# HDSC_HC32M423 register map
Vendor: HDSC Co.,Ltd.; Series: ARMCM4; File version: 1.0
CPU: CM4 r0p1, little endian, MPU, FPU, 4 interrupt priority bits
Registers are 32-bit, read-write, reset 0x0 unless marked. A register's access mark holds for its fields unless they carry their own. Offsets are from the block's base; [hi:lo] are bit positions; {n}, {i} and the like mark numbered series.

## INTC
Base 0x40051000
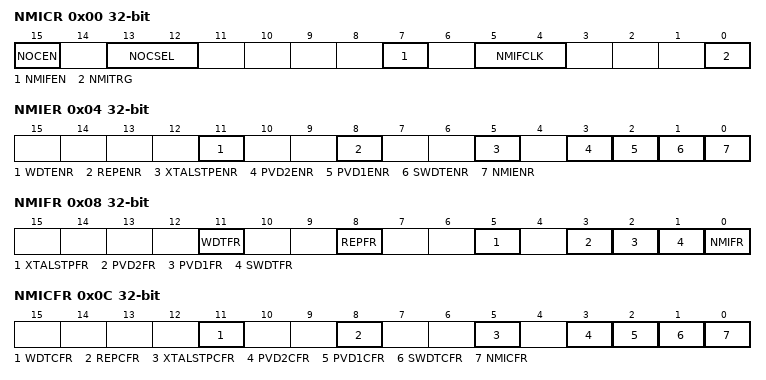
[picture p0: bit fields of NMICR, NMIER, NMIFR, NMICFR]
0x00 NMICR
  [15] NOCEN, [13:12] NOCSEL, [7] NMIFEN, [5:4] NMIFCLK, [0] NMITRG
0x04 NMIER
  [11] WDTENR, [8] REPENR, [5] XTALSTPENR, [3] PVD2ENR, [2] PVD1ENR, [1] SWDTENR, [0] NMIENR
0x08 NMIFR ro
  [11] WDTFR, [8] REPFR, [5] XTALSTPFR, [3] PVD2FR, [2] PVD1FR, [1] SWDTFR, [0] NMIFR
0x0C NMICFR
  [11] WDTCFR, [8] REPCFR, [5] XTALSTPCFR, [3] PVD2CFR, [2] PVD1CFR, [1] SWDTCFR, [0] NMICFR
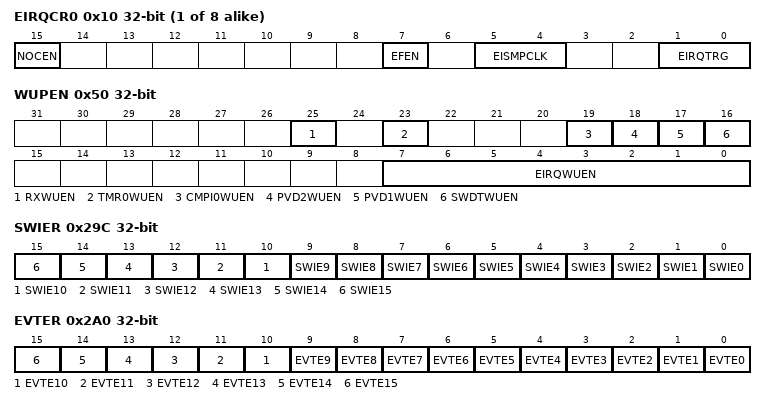
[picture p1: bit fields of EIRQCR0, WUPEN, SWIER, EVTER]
{0x10+4i} EIRQCR{i} (i=0..7)
  [15] NOCEN, [7] EFEN, [5:4] EISMPCLK, [1:0] EIRQTRG
0x50 WUPEN
  [25] RXWUEN, [23] TMR0WUEN, [19] CMPI0WUEN, [18] PVD2WUEN, [17] PVD1WUEN, [16] SWDTWUEN, [7:0] EIRQWUEN
0x54 EIRQFR ro
  [7:0] INT_EIRQFR
0x58 EIRQCFR
  [7:0] INT_EIRQCFR
{0x5C+4i} SEL{i} reset 0x1FF (i=0..7)
  [8:0] ISEL
0x7C SEL8 ro
  [8:0] ISEL
0x80 SEL9 ro reset 0x1
  [8:0] ISEL
0x84 SEL10 ro reset 0x2
  [8:0] ISEL
0x88 SEL11 ro reset 0x3
  [8:0] ISEL
0x8C SEL12 ro reset 0x4
  [8:0] ISEL
0x90 SEL13 ro reset 0x5
  [8:0] ISEL
0x94 SEL14 ro reset 0x6
  [8:0] ISEL
0x98 SEL15 ro reset 0x7
  [8:0] ISEL
0x9C SEL16 ro reset 0x20
  [8:0] ISEL
0xA0 SEL17 ro reset 0x21
  [8:0] ISEL
0xA4 SEL18 ro reset 0x22
  [8:0] ISEL
0xA8 SEL19 ro reset 0x23
  [8:0] ISEL
0xAC SEL20 ro reset 0x28
  [8:0] ISEL
0xB0 SEL21 ro reset 0x29
  [8:0] ISEL
0xB4 SEL22 ro reset 0x2A
  [8:0] ISEL
0xB8 SEL23 ro reset 0x2B
  [8:0] ISEL
0xBC SEL24 ro reset 0x30
  [8:0] ISEL
0xC0 SEL25 ro reset 0x32
  [8:0] ISEL
0xC4 SEL26 ro reset 0x33
  [8:0] ISEL
0xC8 SEL27 ro reset 0x34
  [8:0] ISEL
0xCC SEL28 ro reset 0x37
  [8:0] ISEL
0xD0 SEL29 ro reset 0x40
  [8:0] ISEL
0xD4 SEL30 ro reset 0x41
  [8:0] ISEL
0xD8 SEL31 ro reset 0x42
  [8:0] ISEL
0xDC SEL32 ro reset 0x43
  [8:0] ISEL
0xE0 SEL33 ro reset 0x55
  [8:0] ISEL
0xE4 SEL34 ro reset 0x57
  [8:0] ISEL
0xE8 SEL35 ro reset 0x100
  [8:0] ISEL
0xEC SEL36 ro reset 0x101
  [8:0] ISEL
0xF0 SEL37 ro reset 0x102
  [8:0] ISEL
0xF4 SEL38 ro reset 0x103
  [8:0] ISEL
0xF8 SEL39 ro reset 0x104
  [8:0] ISEL
0xFC SEL40 ro reset 0x105
  [8:0] ISEL
0x100 SEL41 ro reset 0x106
  [8:0] ISEL
0x104 SEL42 ro reset 0x107
  [8:0] ISEL
0x108 SEL43 ro reset 0x108
  [8:0] ISEL
0x10C SEL44 ro reset 0x109
  [8:0] ISEL
0x110 SEL45 ro reset 0x10A
  [8:0] ISEL
0x114 SEL46 ro reset 0x10B
  [8:0] ISEL
0x118 SEL47 ro reset 0x112
  [8:0] ISEL
0x11C SEL48 ro reset 0x113
  [8:0] ISEL
0x120 SEL49 ro reset 0x114
  [8:0] ISEL
0x124 SEL50 ro reset 0x116
  [8:0] ISEL
0x128 SEL51 ro reset 0x117
  [8:0] ISEL
0x12C SEL52 ro reset 0x118
  [8:0] ISEL
0x130 SEL53 ro reset 0x119
  [8:0] ISEL
0x134 SEL54 ro reset 0x11B
  [8:0] ISEL
0x138 SEL55 ro reset 0x11C
  [8:0] ISEL
0x13C SEL56 ro reset 0x11D
  [8:0] ISEL
0x140 SEL57 ro reset 0x11E
  [8:0] ISEL
0x144 SEL58 ro reset 0x120
  [8:0] ISEL
0x148 SEL59 ro reset 0x121
  [8:0] ISEL
0x14C SEL60 ro reset 0x122
  [8:0] ISEL
0x150 SEL61 ro reset 0x123
  [8:0] ISEL
0x154 SEL62 ro reset 0x125
  [8:0] ISEL
0x158 SEL63 ro reset 0x126
  [8:0] ISEL
0x15C SEL64 ro reset 0x127
  [8:0] ISEL
0x160 SEL65 ro reset 0x128
  [8:0] ISEL
0x164 SEL66 ro reset 0x12B
  [8:0] ISEL
0x168 SEL67 ro reset 0x12C
  [8:0] ISEL
0x16C SEL68 ro reset 0x12D
  [8:0] ISEL
0x170 SEL69 ro reset 0x12E
  [8:0] ISEL
0x174 SEL70 ro reset 0x140
  [8:0] ISEL
0x178 SEL71 ro reset 0x141
  [8:0] ISEL
0x17C SEL72 ro reset 0x142
  [8:0] ISEL
0x180 SEL73 ro reset 0x143
  [8:0] ISEL
0x184 SEL74 ro reset 0x144
  [8:0] ISEL
0x188 SEL75 ro reset 0x145
  [8:0] ISEL
0x18C SEL76 ro reset 0x146
  [8:0] ISEL
0x190 SEL77 ro reset 0x147
  [8:0] ISEL
0x194 SEL78 ro reset 0x148
  [8:0] ISEL
0x198 SEL79 ro reset 0x149
  [8:0] ISEL
0x19C SEL80 ro reset 0x14A
  [8:0] ISEL
0x1A0 SEL81 ro reset 0x186
  [8:0] ISEL
0x1A4 SEL82 ro reset 0x1A0
  [8:0] ISEL
0x1A8 SEL83 ro reset 0x1A1
  [8:0] ISEL
0x1AC SEL84 ro reset 0x1A2
  [8:0] ISEL
0x1B0 SEL85 ro reset 0x1A4
  [8:0] ISEL
0x1B4 SEL86 ro reset 0x1A5
  [8:0] ISEL
0x1B8 SEL87 ro reset 0x1A6
  [8:0] ISEL
0x1BC SEL88 ro reset 0x1A7
  [8:0] ISEL
0x1C0 SEL89 ro reset 0x1B0
  [8:0] ISEL
0x1C4 SEL90 ro reset 0x1B1
  [8:0] ISEL
0x1C8 SEL91 ro reset 0x1B2
  [8:0] ISEL
0x1CC SEL92 ro reset 0x1B4
  [8:0] ISEL
0x1D0 SEL93 ro reset 0x1B5
  [8:0] ISEL
0x1D4 SEL94 ro reset 0x1B6
  [8:0] ISEL
0x1D8 SEL95 ro reset 0x1B7
  [8:0] ISEL
0x1DC SEL96 ro reset 0x1B8
  [8:0] ISEL
0x1E0 SEL97 ro reset 0x1C0
  [8:0] ISEL
0x1E4 SEL98 ro reset 0x1C1
  [8:0] ISEL
0x1E8 SEL99 ro reset 0x1C2
  [8:0] ISEL
0x1EC SEL100 ro reset 0x1C3
  [8:0] ISEL
0x29C SWIER
  [n] SWIE{n} (n=0..15)
0x2A0 EVTER
  [n] EVTE{n} (n=0..15)
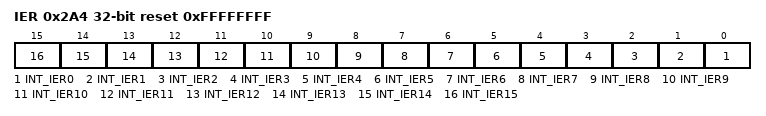
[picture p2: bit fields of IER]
0x2A4 IER reset 0xFFFFFFFF
  [n] INT_IER{n} (n=0..15)
